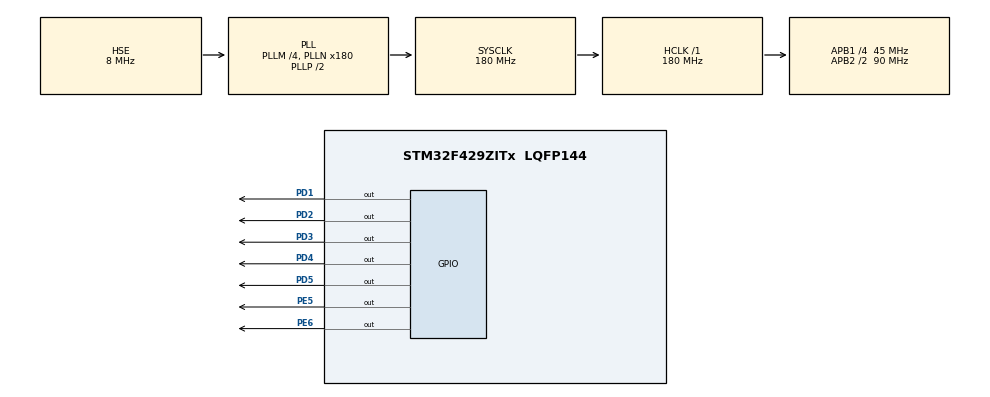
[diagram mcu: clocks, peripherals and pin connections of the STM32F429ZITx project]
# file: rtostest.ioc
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FREERTOS.Tasks01=defaultTask,24,128,StartDefaultTask,Default,NULL,Dynamic,NULL,NULL
Mcu.Family=STM32F4
Mcu.Name=STM32F429ZITx
Mcu.Package=LQFP144
NVIC.PriorityGroup=NVIC_PRIORITYGROUP_4
PD1.Signal=GPIO_Output
PD2.Signal=GPIO_Output
PD3.Signal=GPIO_Output
PD4.Signal=GPIO_Output
PD5.Signal=GPIO_Output
PE5.Signal=GPIO_Output
PE6.Signal=GPIO_Output
PH0/OSC_IN.Mode=HSE-External-Oscillator
PH0/OSC_IN.Signal=RCC_OSC_IN
PH1/OSC_OUT.Mode=HSE-External-Oscillator
PH1/OSC_OUT.Signal=RCC_OSC_OUT
ProjectManager.HeapSize=0x200
ProjectManager.StackSize=0x400
ProjectManager.TargetToolchain=MDK-ARM V5.27
RCC.48MHZClocksFreq_Value=90000000
RCC.AHBFreq_Value=180000000
RCC.APB1CLKDivider=RCC_HCLK_DIV4
RCC.APB1Freq_Value=45000000
RCC.APB1TimFreq_Value=90000000
RCC.APB2CLKDivider=RCC_HCLK_DIV2
RCC.APB2Freq_Value=90000000
RCC.APB2TimFreq_Value=180000000
RCC.CortexFreq_Value=180000000
RCC.HCLKFreq_Value=180000000
RCC.HSE_VALUE=8000000
RCC.HSI_VALUE=16000000
RCC.LSE_VALUE=32768
RCC.PLLM=4
RCC.PLLN=180
RCC.PLLSourceVirtual=RCC_PLLSOURCE_HSE
RCC.SYSCLKFreq_VALUE=180000000
RCC.SYSCLKSource=RCC_SYSCLKSOURCE_PLLCLK
RCC.VCOOutputFreq_Value=360000000
VP_FREERTOS_VS_CMSIS_V2.Mode=CMSIS_V2
board=custom

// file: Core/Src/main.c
/* USER CODE BEGIN Header */
/**
  ******************************************************************************
  * @file           : main.c
  * @brief          : Main program body
  ******************************************************************************
  * @attention
  *
  * <h2><center>&copy; Copyright (c) 2021 STMicroelectronics.
  * All rights reserved.</center></h2>
  *
  * This software component is licensed by ST under Ultimate Liberty license
  * SLA0044, the "License"; You may not use this file except in compliance with
  * the License. You may obtain a copy of the License at:
  *                             www.st.com/SLA0044
  *
  ******************************************************************************
  */
/* USER CODE END Header */
#include "main.h"
#include "cmsis_os.h"
#include "gpio.h"

void SystemClock_Config(void);
void MX_FREERTOS_Init(void);

int main(void)
{

  /* MCU Configuration--------------------------------------------------------*/

  /* Reset of all peripherals, Initializes the Flash interface and the Systick. */
  HAL_Init();

  /* Configure the system clock */
  SystemClock_Config();

  /* Initialize all configured peripherals */
  MX_GPIO_Init();

  /* Init scheduler */
  osKernelInitialize();  /* Call init function for freertos objects (in freertos.c) */
  MX_FREERTOS_Init();
  /* Start scheduler */
  osKernelStart();

  /* We should never get here as control is now taken by the scheduler */
  /* Infinite loop */
  while (1)
  {

  }
}

void SystemClock_Config(void)
{
  RCC_OscInitTypeDef RCC_OscInitStruct = {0};
  RCC_ClkInitTypeDef RCC_ClkInitStruct = {0};

  /** Configure the main internal regulator output voltage
  */
  __HAL_RCC_PWR_CLK_ENABLE();
  __HAL_PWR_VOLTAGESCALING_CONFIG(PWR_REGULATOR_VOLTAGE_SCALE1);
  /** Initializes the RCC Oscillators according to the specified parameters
  * in the RCC_OscInitTypeDef structure.
  */
  RCC_OscInitStruct.OscillatorType = RCC_OSCILLATORTYPE_HSE;
  RCC_OscInitStruct.HSEState = RCC_HSE_ON;
  RCC_OscInitStruct.PLL.PLLState = RCC_PLL_ON;
  RCC_OscInitStruct.PLL.PLLSource = RCC_PLLSOURCE_HSE;
  RCC_OscInitStruct.PLL.PLLM = 4;
  RCC_OscInitStruct.PLL.PLLN = 180;
  RCC_OscInitStruct.PLL.PLLP = RCC_PLLP_DIV2;
  RCC_OscInitStruct.PLL.PLLQ = 4;
  if (HAL_RCC_OscConfig(&RCC_OscInitStruct) != HAL_OK)
  {
    Error_Handler();
  }
  /** Activate the Over-Drive mode
  */
  if (HAL_PWREx_EnableOverDrive() != HAL_OK)
  {
    Error_Handler();
  }
  /** Initializes the CPU, AHB and APB buses clocks
  */
  RCC_ClkInitStruct.ClockType = RCC_CLOCKTYPE_HCLK|RCC_CLOCKTYPE_SYSCLK
                              |RCC_CLOCKTYPE_PCLK1|RCC_CLOCKTYPE_PCLK2;
  RCC_ClkInitStruct.SYSCLKSource = RCC_SYSCLKSOURCE_PLLCLK;
  RCC_ClkInitStruct.AHBCLKDivider = RCC_SYSCLK_DIV1;
  RCC_ClkInitStruct.APB1CLKDivider = RCC_HCLK_DIV4;
  RCC_ClkInitStruct.APB2CLKDivider = RCC_HCLK_DIV2;

  if (HAL_RCC_ClockConfig(&RCC_ClkInitStruct, FLASH_LATENCY_5) != HAL_OK)
  {
    Error_Handler();
  }
}

void Error_Handler(void)
{
  __disable_irq();
  while (1)
  {
  }
}

/************************ (C) COPYRIGHT STMicroelectronics *****END OF FILE****/

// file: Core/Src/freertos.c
/* USER CODE BEGIN Header */
/**
  ******************************************************************************
  * File Name          : freertos.c
  * Description        : Code for freertos applications
  ******************************************************************************
  * @attention
  *
  * <h2><center>&copy; Copyright (c) 2021 STMicroelectronics.
  * All rights reserved.</center></h2>
  *
  * This software component is licensed by ST under Ultimate Liberty license
  * SLA0044, the "License"; You may not use this file except in compliance with
  * the License. You may obtain a copy of the License at:
  *                             www.st.com/SLA0044
  *
  ******************************************************************************
  */
/* USER CODE END Header */

#include "FreeRTOS.h"
#include "task.h"
#include "main.h"
#include "cmsis_os.h"

/* Definitions for defaultTask */
osThreadId_t defaultTaskHandle;
const osThreadAttr_t defaultTask_attributes = {
  .name = "defaultTask",
  .priority = (osPriority_t) osPriorityNormal,
  .stack_size = 128 * 4
};

osThreadId_t secondTaskHandle;
const osThreadAttr_t second_attributes = {
  .name = "secondTask",
  .priority = (osPriority_t) osPriorityNormal,
  .stack_size = 128 * 4
};

void StartDefaultTask(void *argument);
void StartsecondTask(void *argument);

void MX_FREERTOS_Init(void); /* (MISRA C 2004 rule 8.1) */

void MX_FREERTOS_Init(void) {

  /* Create the thread(s) */
  /* creation of defaultTask */
  defaultTaskHandle = osThreadNew(StartDefaultTask, NULL, &defaultTask_attributes);
	secondTaskHandle = osThreadNew(StartsecondTask, NULL, &second_attributes);

}

void StartDefaultTask(void *argument)
{
  /* USER CODE BEGIN StartDefaultTask */
  /* Infinite loop */
  for(;;)
  {
    HAL_GPIO_TogglePin(GPIOE, GPIO_PIN_6);
		HAL_Delay(1000);
  }
  /* USER CODE END StartDefaultTask */
}

void StartsecondTask(void *argument)
{
  /* USER CODE BEGIN StartDefaultTask */
  /* Infinite loop */
  for(;;)
  {
    HAL_GPIO_TogglePin(GPIOE, GPIO_PIN_5);
		HAL_Delay(500);
  }
  /* USER CODE END StartDefaultTask */
}

/************************ (C) COPYRIGHT STMicroelectronics *****END OF FILE****/
